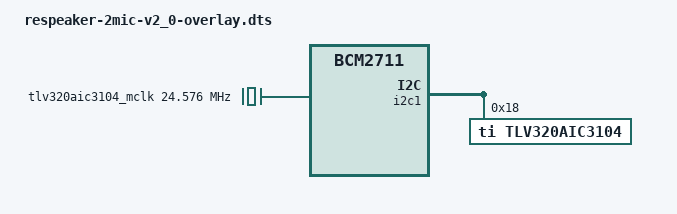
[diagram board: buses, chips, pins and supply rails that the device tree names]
/*
 * ReSpeaker 2-Mics Pi HAT v2.0 device-tree overlay.
 *
 * Vendored verbatim from Seeed Studio, MIT licensed. Upstream:
 *   https://github.com/Seeed-Studio/seeed-linux-dtoverlays
 *   overlays/rpi/respeaker-2mic-v2_0-overlay.dts
 *
 * Why this is here rather than fetched at build time: it is 92 lines, and a
 * copy in the tree keeps the image build reproducible, offline-capable, and
 * immune to upstream moving the file.
 *
 * Why it is needed at all: `seeed-2mic-voicecard` -- which older guides, and
 * this project's own SETUP.md, told you to use -- is NOT an overlay that
 * ships with Raspberry Pi OS. It belongs to Seeed's out-of-tree
 * seeed-voicecard DKMS driver, which broke after kernel 5.10 and which Seeed
 * no longer recommend. The v2.0 board's TLV320AIC3104 codec is supported by
 * the mainline SND_SOC_TLV320AIC3X driver already in the kernel, so all that
 * is actually required is this overlay describing how it is wired.
 *
 * Note it sets simple-audio-card,name = "seeed2micvoicec", which is the ALSA
 * card name src/config.py and config/config.example.json already expect.
 *
 * Compile with:  dtc -@ -I dts -O dtb -o respeaker-2mic-v2_0.dtbo <this file>
 * The -@ is required: the overlay targets &i2c1 and &sound by phandle.
 *
 * For a v1.0 board (WM8960 codec) this file is not used at all -- that one
 * has an in-tree overlay. Build with LV_AUDIO_OVERLAY=wm8960-soundcard.
 */
/dts-v1/;
/plugin/;

/ {
	compatible = "brcm,bcm2835", "brcm,bcm2708", "brcm,bcm2709", "brcm,bcm2711";
	
	fragment@0 {
		target-path="/";
		__overlay__ {
			hardware = "reSpeaker V2.0";
		};
	};
	
	fragment@1 {
		target-path="/";
		__overlay__ {
			
			tlv320aic3104_mclk: tlv320aic3104_mclk {
				#clock-cells = <0>;
				compatible = "fixed-clock";
				clock-frequency = <24576000>;
			};
		};
	};
	
	fragment@2 {
		target = <&i2c1>;
		__overlay__ {
			#address-cells = <1>;
			#size-cells = <0>;
			status = "okay";
			
			tlv320aic3104: tlv320aic3104@18 {
				#sound-dai-cells = <0>;
				compatible = "ti,tlv320aic3104";
				reg = <0x18>;
				ai3x-micbias-vg = <2>;// set MICBIAS to 2.5v
			};
		};
	};
	
	fragment@3 {
		target = <&i2s_clk_consumer>;
		__overlay__ {
			status = "okay";
		};
	};
	
	fragment@4 {
		target = <&sound>;
		slave_overlay: __overlay__ {
			compatible = "simple-audio-card";
			simple-audio-card,format = "i2s";
			simple-audio-card,name = "seeed2micvoicec";
			i2s-controller = <&i2s_clk_consumer>;
			status = "okay";
			
			simple-audio-card,widgets =
			"Headphone", "Headphone Jack",
			"Line", "Line In";
			simple-audio-card,routing =
			"Headphone Jack",       "HPLOUT",
			"Headphone Jack",       "HPROUT",
			"LINE1L",               "Line In",
			"LINE1R",               "Line In";
			
			simple-audio-card,bitclock-master = <&sound_master>;
			simple-audio-card,frame-master = <&sound_master>;
			
			simple-audio-card,cpu {
				sound-dai = <&i2s_clk_consumer>;
			};
			sound_master: simple-audio-card,codec {
				#sound-dai-cells = <0>;
				sound-dai = <&tlv320aic3104>;
				clocks = <&tlv320aic3104_mclk>;
				clock-names = "mclk";
			};
		};
	};
	
	__overrides__ {
	};
};

